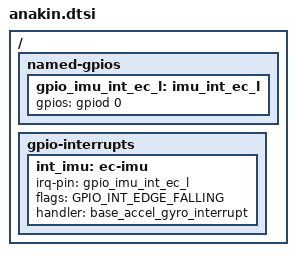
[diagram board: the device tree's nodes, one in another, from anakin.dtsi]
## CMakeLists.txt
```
# Copyright 2026 The ChromiumOS Authors
# Use of this source code is governed by a BSD-style license that can be
# found in the LICENSE file.

# SPDX-License-Identifier: Apache-2.0

cmake_minimum_required(VERSION 3.20.0)

# Initialize Zephyr
find_package(Zephyr REQUIRED HINTS $ENV{ZEPHYR_BASE})
project(skywalker_tests)

add_subdirectory(${PLATFORM_EC}/zephyr/test/test_utils test_utils)

zephyr_include_directories(
	"${PLATFORM_EC_PROGRAM_DIR}/skywalker/include"
	"${PLATFORM_EC_PROGRAM_DIR}/skywalker/skywalker/include"
	include)

target_sources(app PRIVATE
	src/main.c
)

target_sources_ifdef(CONFIG_TEST_SKYWALKER app PRIVATE
	${PLATFORM_EC_PROGRAM_DIR}/skywalker/skywalker/src/sensor.c
	src/test_skywalker.c
)

target_sources_ifdef(CONFIG_TEST_ANAKIN app PRIVATE
	${PLATFORM_EC_PROGRAM_DIR}/skywalker/anakin/src/sensor.c
	src/test_anakin.c
)
```

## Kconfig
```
# Copyright 2026 The ChromiumOS Authors
# Use of this source code is governed by a BSD-style license that can be
# found in the LICENSE file.

choice
    prompt "Select the test suite"

config TEST_SKYWALKER
    bool "Run the tests intended for Skywalker"
    help
      Enable the Skywalker test suite.

config TEST_ANAKIN
    bool "Run the tests intended for Anakin"
    help
      Enable the Anakin test suite.

endchoice

# Pull Zephyr test support
source "Kconfig.zephyr"
```

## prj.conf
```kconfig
# Copyright 2026 The ChromiumOS Authors
# Use of this source code is governed by a BSD-style license that can be
# found in the LICENSE file.

CONFIG_ZTEST=y
CONFIG_ZTEST_ASSERT_VERBOSE=1
CONFIG_ASSERT=y

CONFIG_PLATFORM_EC=y
CONFIG_CROS_EC=y
CONFIG_EMUL=y
CONFIG_SHIMMED_TASKS=n
CONFIG_PLATFORM_EC_GPIO_INIT_PRIORITY=49
CONFIG_PLATFORM_EC_HOOKS=y
CONFIG_PLATFORM_EC_TIMER=y

CONFIG_AP_ARM_MTK_MT8189=y
CONFIG_PLATFORM_EC_CHIPSET_RESUME_INIT_HOOK=y
CONFIG_PLATFORM_EC_EXTPOWER_GPIO=y
CONFIG_PLATFORM_EC_POWERSEQ=y
CONFIG_PLATFORM_EC_POWERSEQ_HOST_SLEEP=y
CONFIG_PLATFORM_EC_POWER_SLEEP_FAILURE_DETECTION=y

CONFIG_PLATFORM_EC_HOSTCMD=y
CONFIG_PLATFORM_EC_HOSTCMD_TYPEC_STATUS=n

CONFIG_PLATFORM_EC_VBOOT_HASH=n
CONFIG_PLATFORM_EC_VBOOT_EFS2=n

CONFIG_PLATFORM_EC_USBC=y
CONFIG_PLATFORM_EC_USBC_PPC=n
CONFIG_PLATFORM_EC_USBC_SS_MUX=n
CONFIG_PLATFORM_EC_USB_CHARGER=n
CONFIG_PLATFORM_EC_USB_PD_CONTROLLER=y
CONFIG_PLATFORM_EC_USB_PD_MAX_CURRENT_MA=3250
CONFIG_PLATFORM_EC_USB_PD_MAX_POWER_MW=65000
CONFIG_PLATFORM_EC_USB_PD_TCPMV2=n
CONFIG_PLATFORM_EC_USB_PD_VBUS_MEASURE_PDC=y
CONFIG_PLATFORM_EC_PD_POWER_SUPPLY_TURN_OFF_DELAY=5000
CONFIG_PLATFORM_EC_PD_POWER_SUPPLY_TURN_ON_DELAY=5000
CONFIG_USBC_PDC_DRIVEN_CCD=y
CONFIG_PDC_POWER_MGMT_POWER_STATE_DEBOUNCE_PERIOD_MS=0

CONFIG_PLATFORM_EC_BATTERY_FUEL_GAUGE=y
CONFIG_PLATFORM_EC_CHARGER_ISL9238=y
CONFIG_PLATFORM_EC_CHARGER_SENSE_RESISTOR=10
CONFIG_PLATFORM_EC_CHARGER_SENSE_RESISTOR_AC=10

CONFIG_PLATFORM_EC_MOTIONSENSE=y
CONFIG_PLATFORM_EC_ACCEL_LIS2DW12=y
CONFIG_PLATFORM_EC_ACCEL_BMA4XX=y

CONFIG_PLATFORM_EC_BACKLIGHT_LID=n
CONFIG_PLATFORM_EC_LID_SWITCH=y
CONFIG_PLATFORM_EC_POWER_BUTTON=y
CONFIG_PLATFORM_EC_SWITCH=n
CONFIG_PLATFORM_EC_TABLET_MODE=y
```

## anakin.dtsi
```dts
/* Copyright 2026 The ChromiumOS Authors
 * Use of this source code is governed by a BSD-style license that can be
 * found in the LICENSE file.
 */

#include "../program/skywalker/anakin/cbi.dtsi"

/ {
	named-gpios {
		gpio_imu_int_ec_l: imu_int_ec_l {
			gpios = <&gpiod 0 (GPIO_INPUT | GPIO_VOLTAGE_1P8)>;
		};
	};

	gpio-interrupts {
		int_imu: ec-imu {
			irq-pin = <&gpio_imu_int_ec_l>;
			flags = <GPIO_INT_EDGE_FALLING>;
			handler = "base_accel_gyro_interrupt";
		};
	};
};
```

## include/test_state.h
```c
/* Copyright 2026 The ChromiumOS Authors
 * Use of this source code is governed by a BSD-style license that can be
 * found in the LICENSE file.
 */

#ifndef PLATFORM_EC_ZEPHYR_TEST_SKYWALKER_INCLUDE_TEST_STATE_H_
#define PLATFORM_EC_ZEPHYR_TEST_SKYWALKER_INCLUDE_TEST_STATE_H_

#include <stdbool.h>

struct test_state {
	bool ec_app_main_run;
};

bool skywalker_predicate_post_main(const void *state);

#endif /* PLATFORM_EC_ZEPHYR_TEST_SKYWALKER_INCLUDE_TEST_STATE_H_ */
```

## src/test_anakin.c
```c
/* Copyright 2026 The ChromiumOS Authors
 * Use of this source code is governed by a BSD-style license that can be
 * found in the LICENSE file.
 */

#include "ap_power/ap_power.h"
#include "ap_power/ap_power_events.h"
#include "cros_cbi.h"
#include "gpio/gpio_int.h"
#include "hooks.h"
#include "motion_sense.h"
#include "tablet_mode.h"
#include "test_state.h"

#include <zephyr/drivers/gpio.h>
#include <zephyr/drivers/gpio/gpio_emul.h>
#include <zephyr/fff.h>
#include <zephyr/kernel.h>
#include <zephyr/ztest.h>

FAKE_VALUE_FUNC(int, cros_cbi_get_fw_config, enum cbi_fw_config_field_id,
		uint32_t *);
FAKE_VALUE_FUNC(bool, cros_cbi_ssfc_check_match, enum cbi_ssfc_value_id);
FAKE_VOID_FUNC(gmr_tablet_switch_disable);
FAKE_VOID_FUNC(bma4xx_interrupt, enum gpio_signal);
FAKE_VOID_FUNC(lis2dw12_interrupt, enum gpio_signal);
FAKE_VOID_FUNC(bmi3xx_interrupt, enum gpio_signal);
FAKE_VOID_FUNC(lsm6dsm_interrupt, enum gpio_signal);
FAKE_VOID_FUNC(xhci_interrupt, enum gpio_signal);

static uint32_t mock_form_factor = CONVERTIBLE;
static int mock_cbi_ret;

static int mock_cros_cbi_get_fw_config(enum cbi_fw_config_field_id field_id,
				       uint32_t *value)
{
	if (field_id != FORM_FACTOR) {
		return -EINVAL;
	}
	if (mock_cbi_ret != 0) {
		return mock_cbi_ret;
	}
	*value = mock_form_factor;
	return 0;
}

static void pulse_sensor_irqs(void)
{
	const struct gpio_dt_spec *lid_irq =
		GPIO_DT_FROM_NODELABEL(gpio_lid_accel_int_ec_l);
	const struct gpio_dt_spec *imu_irq =
		GPIO_DT_FROM_NODELABEL(gpio_imu_int_ec_l);

	zassert_ok(gpio_emul_input_set_dt(lid_irq, 1));
	zassert_ok(gpio_emul_input_set_dt(imu_irq, 1));
	k_sleep(K_MSEC(1));
	zassert_ok(gpio_emul_input_set_dt(lid_irq, 0));
	zassert_ok(gpio_emul_input_set_dt(imu_irq, 0));
	k_sleep(K_MSEC(1));
	zassert_ok(gpio_emul_input_set_dt(lid_irq, 1));
	zassert_ok(gpio_emul_input_set_dt(imu_irq, 1));
}

static void anakin_before(void *fixture)
{
	RESET_FAKE(cros_cbi_get_fw_config);
	RESET_FAKE(cros_cbi_ssfc_check_match);
	RESET_FAKE(gmr_tablet_switch_disable);
	RESET_FAKE(bma4xx_interrupt);
	RESET_FAKE(lis2dw12_interrupt);
	RESET_FAKE(bmi3xx_interrupt);
	RESET_FAKE(lsm6dsm_interrupt);

	mock_form_factor = CONVERTIBLE;
	mock_cbi_ret = 0;
	cros_cbi_get_fw_config_fake.custom_fake = mock_cros_cbi_get_fw_config;
}

ZTEST(anakin, test_clamshell_sensor_irqs_stay_disabled_on_ap_startup)
{
	mock_form_factor = CLAMSHELL;
	hook_notify(HOOK_INIT);

	zassert_equal(gmr_tablet_switch_disable_fake.call_count, 1);
	zassert_equal(motion_sensor_count, 0);

	/*
	 * Transition AP to startup and shutdown; on a clamshell SKU without
	 * motion sensors populated, int_lid_accel and int_imu must remain
	 * disabled.
	 */
	ap_power_ev_send_callbacks(AP_POWER_STARTUP);

	RESET_FAKE(bma4xx_interrupt);
	RESET_FAKE(lis2dw12_interrupt);
	RESET_FAKE(bmi3xx_interrupt);
	RESET_FAKE(lsm6dsm_interrupt);

	pulse_sensor_irqs();

	zassert_equal(bma4xx_interrupt_fake.call_count, 0);
	zassert_equal(lis2dw12_interrupt_fake.call_count, 0);
	zassert_equal(bmi3xx_interrupt_fake.call_count, 0);
	zassert_equal(lsm6dsm_interrupt_fake.call_count, 0);

	ap_power_ev_send_callbacks(AP_POWER_SHUTDOWN);
}

ZTEST(anakin, test_convertible_sensor_irqs_and_ssfc)
{
	mock_form_factor = CONVERTIBLE;
	cros_cbi_ssfc_check_match_fake.return_val = true;
	hook_notify(HOOK_INIT);

	ap_power_ev_send_callbacks(AP_POWER_STARTUP);
	pulse_sensor_irqs();

	zassert_equal(bma4xx_interrupt_fake.call_count, 1);
	zassert_equal(lis2dw12_interrupt_fake.call_count, 0);
	zassert_equal(bmi3xx_interrupt_fake.call_count, 1);
	zassert_equal(lsm6dsm_interrupt_fake.call_count, 0);

	/* Switch to alternate sensors (lis2dw12 + lsm6dsm) */
	cros_cbi_ssfc_check_match_fake.return_val = false;
	hook_notify(HOOK_INIT);

	RESET_FAKE(bma4xx_interrupt);
	RESET_FAKE(lis2dw12_interrupt);
	RESET_FAKE(bmi3xx_interrupt);
	RESET_FAKE(lsm6dsm_interrupt);

	pulse_sensor_irqs();

	zassert_equal(bma4xx_interrupt_fake.call_count, 0);
	zassert_equal(lis2dw12_interrupt_fake.call_count, 1);
	zassert_equal(bmi3xx_interrupt_fake.call_count, 0);
	zassert_equal(lsm6dsm_interrupt_fake.call_count, 1);

	/* Verify AP_POWER_SHUTDOWN disables both interrupts */
	ap_power_ev_send_callbacks(AP_POWER_SHUTDOWN);

	RESET_FAKE(bma4xx_interrupt);
	RESET_FAKE(lis2dw12_interrupt);
	RESET_FAKE(bmi3xx_interrupt);
	RESET_FAKE(lsm6dsm_interrupt);

	pulse_sensor_irqs();

	zassert_equal(bma4xx_interrupt_fake.call_count, 0);
	zassert_equal(lis2dw12_interrupt_fake.call_count, 0);
	zassert_equal(bmi3xx_interrupt_fake.call_count, 0);
	zassert_equal(lsm6dsm_interrupt_fake.call_count, 0);
}

ZTEST(anakin, test_cbi_read_error)
{
	mock_cbi_ret = -EINVAL;
	hook_notify(HOOK_INIT);
	zassert_equal(gmr_tablet_switch_disable_fake.call_count, 0);
}

ZTEST_SUITE(anakin, skywalker_predicate_post_main, NULL, anakin_before, NULL,
	    NULL);
```
